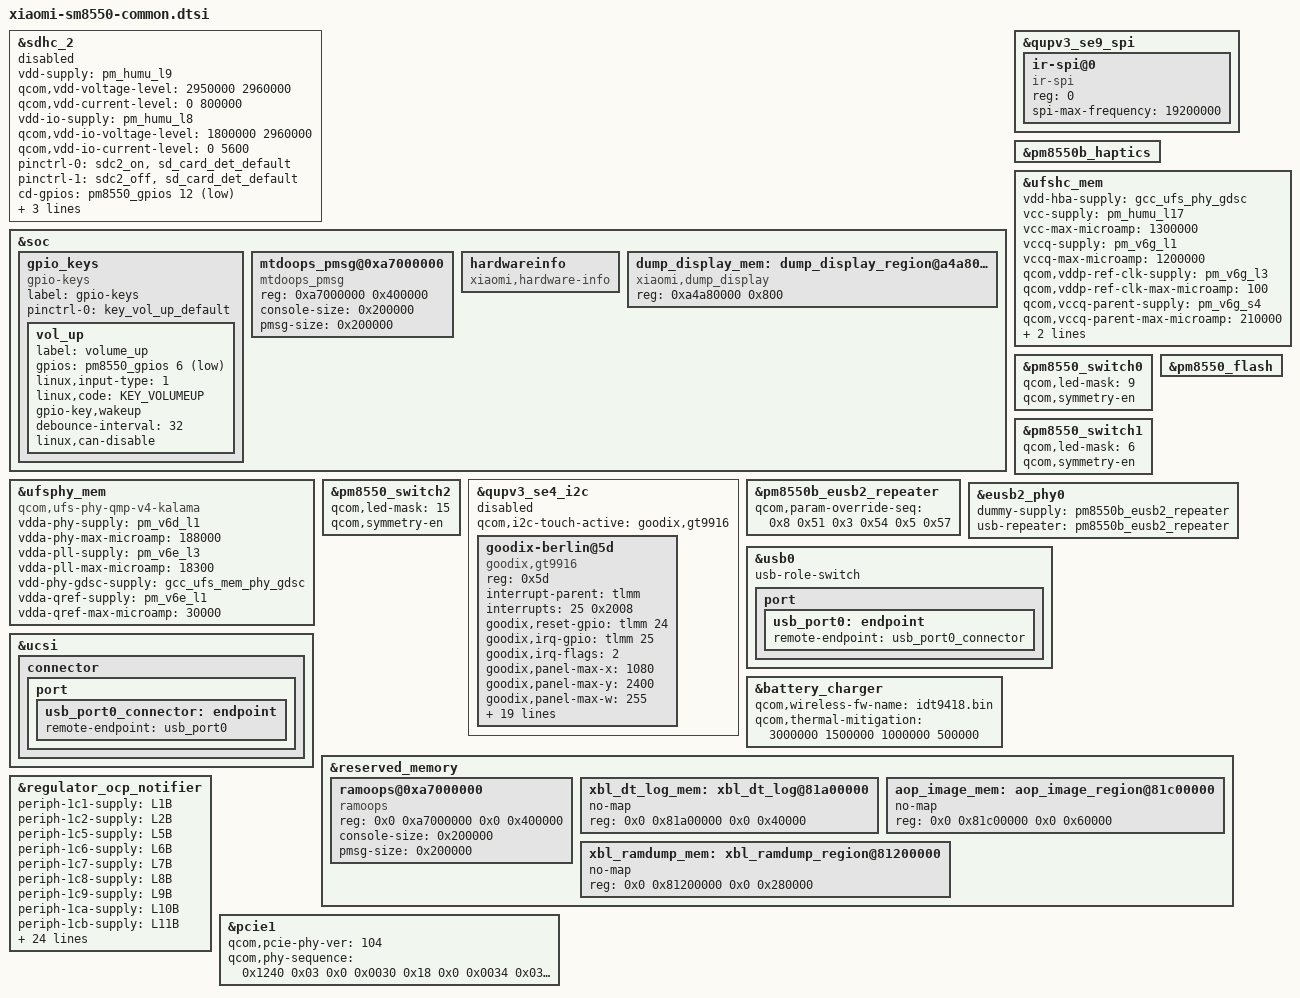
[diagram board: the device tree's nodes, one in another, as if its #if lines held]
#include <dt-bindings/gpio/gpio.h>
#include <dt-bindings/input/input.h>
#include <dt-bindings/clock/qcom,gcc-kalama.h>

#include "kalama-pmic-overlay.dtsi"
#include "kalama-thermal-overlay.dtsi"

&sdhc_2 {
	status = "disabled";
	vdd-supply = <&pm_humu_l9>;
	qcom,vdd-voltage-level = <2950000 2960000>;
	qcom,vdd-current-level = <0 800000>;

	vdd-io-supply = <&pm_humu_l8>;
	qcom,vdd-io-voltage-level = <1800000 2960000>;
	qcom,vdd-io-current-level = <0 5600>;

	pinctrl-names = "default", "sleep";
	pinctrl-0 = <&sdc2_on>, <&sd_card_det_default>;
	pinctrl-1 = <&sdc2_off>, <&sd_card_det_default>;

	cd-gpios = <&pm8550_gpios 12 GPIO_ACTIVE_LOW>;

	resets = <&gcc GCC_SDCC2_BCR>;
	reset-names = "core_reset";

	qcom,iommu-dma = "fastmap";
	qcom,uses_level_shifter;
};

&soc {
	gpio_keys {
		compatible = "gpio-keys";
		label = "gpio-keys";

		pinctrl-names = "default";
		pinctrl-0 = <&key_vol_up_default>;

		vol_up {
			label = "volume_up";
			gpios = <&pm8550_gpios 6 GPIO_ACTIVE_LOW>;
			linux,input-type = <1>;
			linux,code = <KEY_VOLUMEUP>;
			gpio-key,wakeup;
			debounce-interval = <32>;
			linux,can-disable;
		};
	};

	mtdoops_pmsg@0xa7000000 {
		compatible = "mtdoops_pmsg";
		reg = <0xa7000000 0x400000>;
		console-size = <0x200000>;
		pmsg-size = <0x200000>;
	};

	hardwareinfo {
		compatible = "xiaomi,hardware-info";
		status = "ok";
	};

	dump_display_mem: dump_display_region@a4a80000 {
		compatible = "xiaomi,dump_display";
		reg = <0xa4a80000  0x800>;
	};
};

&qupv3_se9_spi {
	status = "ok";
	ir-spi@0 {
		compatible = "ir-spi";
		reg = <0>;
		spi-max-frequency = <19200000>;
		status = "ok";
	};
};

&pm8550b_haptics {
	status = "okay";
};

&ufsphy_mem {
	compatible = "qcom,ufs-phy-qmp-v4-kalama";

	/* VDDA_UFS_CORE */
	vdda-phy-supply = <&pm_v6d_l1>;
	vdda-phy-max-microamp = <188000>;

	/* VDDA_UFS_0_1P2 */
	vdda-pll-supply = <&pm_v6e_l3>;
	vdda-pll-max-microamp = <18300>;

	/* Phy GDSC for VDD_MX, always on */
	vdd-phy-gdsc-supply = <&gcc_ufs_mem_phy_gdsc>;

	/* Qref power supply, Refer Qref diagram */
	vdda-qref-supply = <&pm_v6e_l1>;
	vdda-qref-max-microamp = <30000>;

	status = "ok";
};

&ufshc_mem {
	vdd-hba-supply = <&gcc_ufs_phy_gdsc>;

	vcc-supply = <&pm_humu_l17>;
	vcc-max-microamp = <1300000>;

	vccq-supply = <&pm_v6g_l1>;
	vccq-max-microamp = <1200000>;

	/* VDD_PX10 is voted for the ufs_reset_n */
	qcom,vddp-ref-clk-supply = <&pm_v6g_l3>;
	qcom,vddp-ref-clk-max-microamp = <100>;

	qcom,vccq-parent-supply = <&pm_v6g_s4>;
	qcom,vccq-parent-max-microamp = <210000>;

	reset-gpios = <&tlmm 210 GPIO_ACTIVE_LOW>;
	resets = <&gcc GCC_UFS_PHY_BCR>;
	reset-names = "rst";

	status = "ok";
};

&pm8550_switch0 {
	qcom,led-mask = <9>; /* Channels 1 & 4 */
	qcom,symmetry-en;
};

&pm8550_switch1 {
	qcom,led-mask = <6>; /* Channels 2 & 3 */
	qcom,symmetry-en;
};

&pm8550_switch2 {
	qcom,led-mask = <15>; /* All Channels */
	qcom,symmetry-en;
};

&pm8550_flash {
	status = "ok";
};


&qupv3_se4_i2c {
	#address-cells = <1>;
	#size-cells = <0>;

	status = "disabled";
	qcom,i2c-touch-active = "goodix,gt9916";

	goodix-berlin@5d {
		compatible = "goodix,gt9916";
		reg = <0x5d>;
		interrupt-parent = <&tlmm>;
		interrupts = <25 0x2008>;
		goodix,reset-gpio = <&tlmm 24 0x00>;
		goodix,irq-gpio = <&tlmm 25 0x2008>;
		goodix,irq-flags = <2>;
		goodix,panel-max-x = <1080>;
		goodix,panel-max-y = <2400>;
		goodix,panel-max-w = <255>;
		goodix,panel-max-p = <4096>;
		goodix,firmware-name = "goodix_firmware_i2c.bin";
		goodix,config-name = "goodix_cfg_group_i2c.bin";
		goodix,avdd-name = "avdd";
		goodix,iovdd-name = "iovdd";
		invert_xy;
		avdd-supply = <&L14B>;
		iovdd-supply = <&L12B>;
		goodix,touch-type = "primary";
		goodix,qts_en;
		qts,trusted-touch-mode = "vm_mode";
		qts,touch-environment = "pvm";
		qts,trusted-touch-type = "primary";
		qts,trusted-touch-spi-irq = <569>;
		qts,trusted-touch-io-bases = <0xa90000>;
		qts,trusted-touch-io-sizes = <0x1000>;
		qts,trusted-touch-vm-gpio-list = <&tlmm 44 0 &tlmm 45 0 &tlmm 46 0
						&tlmm 47 0 &tlmm 24 0 &tlmm 25 0x2008>;
	};
};

&pm8550b_eusb2_repeater {
	qcom,param-override-seq =
		/* <value reg_offset> */
		/* Adjust HS trasmit amplitude */
		<0x8 0x51
		/* Squelch detection threshold */
		 0x3 0x54
		/* Tx pre-emphasis tuning */
		 0x5 0x57>;
};

&eusb2_phy0 {
	dummy-supply = <&pm8550b_eusb2_repeater>;
	usb-repeater = <&pm8550b_eusb2_repeater>;
};

&usb0 {
	usb-role-switch;
	port {
		usb_port0: endpoint {
			remote-endpoint = <&usb_port0_connector>;
		};
	};
};

&ucsi {
	connector {
		port {
			usb_port0_connector: endpoint {
				remote-endpoint = <&usb_port0>;
			};
		};
	};
};

&battery_charger {
	qcom,wireless-fw-name = "idt9418.bin";
	qcom,thermal-mitigation = <3000000 1500000 1000000 500000>;
};

&reserved_memory {
	#address-cells = <2>;
	#size-cells = <2>;
	ranges;

	ramoops@0xa7000000 {
		compatible = "ramoops";
		reg = <0x0 0xa7000000 0x0 0x400000>;
		console-size = <0x200000>;
		pmsg-size = <0x200000>;
	};

	// xiami splits xbl_dt_log_merged_mem into the following
	// 3 regions, just like older days
	xbl_dt_log_mem: xbl_dt_log@81a00000 {
	       no-map;
	       reg = <0x0 0x81a00000 0x0 0x40000>;
	};

	aop_image_mem: aop_image_region@81c00000 {
	       no-map;
	       reg = <0x0 0x81c00000 0x0 0x60000>;
	};

	xbl_ramdump_mem: xbl_ramdump_region@81200000 {
		no-map;
		reg = <0x0 0x81200000 0x0 0x280000>;
	};
};
#if defined(ISHTAR_REGULATOR_OCP)
&regulator_ocp_notifier {
        periph-1c1-supply = <&L1B>;
        periph-1c2-supply = <&L2B>;
        periph-1c5-supply = <&L5B>;
        periph-1c6-supply = <&L6B>;
        periph-1c7-supply = <&L7B>;
        periph-1c8-supply = <&L8B>;
        periph-1c9-supply = <&L9B>;
        periph-1ca-supply = <&L10B>;
        periph-1cb-supply = <&L11B>;
        periph-1cc-supply = <&L12B>;
        periph-1ce-supply = <&L14B>;
        periph-1cf-supply = <&L15B>;
        periph-1d0-supply = <&L16B>;
        periph-1d1-supply = <&L17B>;
        periph-2c1-supply = <&L1C>;
        periph-3c1-supply = <&L1D>;
        periph-3c2-supply = <&L2D_LEVEL>;
        periph-4c1-supply = <&L1E>;
        periph-4c2-supply = <&L2E>;
        periph-4c3-supply = <&L3E>;
        periph-5c1-supply = <&L1F>;
        periph-5c2-supply = <&L2F>;
        periph-5c3-supply = <&L3F>;
        periph-6c1-supply = <&L1G>;
        periph-6c2-supply = <&L2G>;
        periph-6c3-supply = <&L3G>;
        periph-ac1-supply = <&L1K>;
        periph-ac2-supply = <&L2K>;
        periph-ac3-supply = <&L3K>;
        periph-ac4-supply = <&L4K>;
        periph-ac5-supply = <&L5K>;
        periph-ac6-supply = <&L6K>;
        periph-ac7-supply = <&L7K>;
};
#elif defined(VERMEER_REGULATOR_OCP)
&regulator_ocp_notifier {
        periph-1c1-supply = <&L1B>;
        periph-1c2-supply = <&L2B>;
        periph-1c5-supply = <&L5B>;
        periph-1c6-supply = <&L6B>;
        periph-1c7-supply = <&L7B>;
        periph-1c8-supply = <&L8B>;
        periph-1c9-supply = <&L9B>;
        periph-1ca-supply = <&L10B>;
        periph-1cb-supply = <&L11B>;
        periph-1cc-supply = <&L12B>;
        periph-1ce-supply = <&L14B>;
        periph-1cf-supply = <&L15B>;
        periph-1d0-supply = <&L16B>;
        periph-1d1-supply = <&L17B>;
        periph-2c1-supply = <&L1C>;
        periph-3c1-supply = <&L1D>;
        periph-3c2-supply = <&L2D_LEVEL>;
        periph-4c1-supply = <&L1E>;
        periph-4c2-supply = <&L2E>;
        periph-4c3-supply = <&L3E>;
        periph-5c1-supply = <&L1F>;
        periph-5c2-supply = <&L2F>;
        periph-5c3-supply = <&L3F>;
        periph-6c1-supply = <&L1G>;
        periph-6c2-supply = <&L2G>;
        periph-6c3-supply = <&L3G>;
        periph-ac1-supply = <&L1K>;
        periph-ac2-supply = <&L2K>;
        periph-ac3-supply = <&L3K>;
        periph-ac4-supply = <&L4K>;
        periph-ac5-supply = <&L5K>;
        periph-ac6-supply = <&L6K>;
        periph-ac7-supply = <&L7K>;
};
#elif defined(BABYLON_REGULATOR_OCP)
&regulator_ocp_notifier {
        periph-1c1-supply = <&L1B>;
        periph-1c2-supply = <&L2B>;
        periph-1c5-supply = <&L5B>;
        periph-1c6-supply = <&L6B>;
        periph-1c7-supply = <&L7B>;
        periph-1c8-supply = <&L8B>;
        periph-1c9-supply = <&L9B>;
        periph-1ca-supply = <&L10B>;
        periph-1cb-supply = <&L11B>;
        periph-1cc-supply = <&L12B>;
        periph-1ce-supply = <&L14B>;
        periph-1cf-supply = <&L15B>;
        periph-1d0-supply = <&L16B>;
        periph-1d1-supply = <&L17B>;
        periph-2c1-supply = <&L1C>;
        periph-3c1-supply = <&L1D>;
        periph-3c2-supply = <&L2D_LEVEL>;
        periph-4c1-supply = <&L1E>;
        periph-4c2-supply = <&L2E>;
        periph-4c3-supply = <&L3E>;
        periph-5c1-supply = <&L1F>;
        periph-5c2-supply = <&L2F>;
        periph-5c3-supply = <&L3F>;
        periph-6c1-supply = <&L1G>;
        periph-6c2-supply = <&L2G>;
        periph-6c3-supply = <&L3G>;
        periph-ac1-supply = <&L1K>;
        periph-ac2-supply = <&L2K>;
        periph-ac3-supply = <&L3K>;
        periph-ac4-supply = <&L4K>;
        periph-ac5-supply = <&L5K>;
        periph-ac6-supply = <&L6K>;
        periph-ac7-supply = <&L7K>;
};
#elif defined(SOCRATES_REGULATOR_OCP)
&regulator_ocp_notifier {
	periph-1c1-supply = <&L1B>;
	periph-1c2-supply = <&L2B>;
	periph-1c5-supply = <&L5B>;
	periph-1c6-supply = <&L6B>;
	periph-1c7-supply = <&L7B>;
	periph-1c8-supply = <&L8B>;
	periph-1c9-supply = <&L9B>;
	periph-1ca-supply = <&L10B>;
	periph-1cb-supply = <&L11B>;
	periph-1cc-supply = <&L12B>;
	periph-1cd-supply = <&L13B>;
	periph-1ce-supply = <&L14B>;
	periph-1cf-supply = <&L15B>;
	periph-1d0-supply = <&L16B>;
	periph-1d1-supply = <&L17B>;
	periph-2c1-supply = <&L1C>;
	periph-3c1-supply = <&L1D>;
	periph-3c2-supply = <&L2D_LEVEL>;
	periph-4c1-supply = <&L1E>;
	periph-4c2-supply = <&L2E>;
	periph-4c3-supply = <&L3E>;
	periph-5c1-supply = <&L1F>;
	periph-5c2-supply = <&L2F>;
	periph-5c3-supply = <&L3F>;
	periph-6c1-supply = <&L1G>;
	periph-6c2-supply = <&L2G>;
	periph-6c3-supply = <&L3G>;
	periph-ac1-supply = <&L1K>;
	periph-ac2-supply = <&L2K>;
	periph-ac3-supply = <&L3K>;
	periph-ac4-supply = <&L4K>;
	periph-ac5-supply = <&L5K>;
	periph-ac6-supply = <&L6K>;
	periph-ac7-supply = <&L7K>;
};
#elif defined(FUXI_NUWA_REGULATOR_OCP)
&regulator_ocp_notifier {
        periph-1c1-supply = <&L1B>;
        periph-1c2-supply = <&L2B>;
        periph-1c5-supply = <&L5B>;
        periph-1c6-supply = <&L6B>;
        periph-1c7-supply = <&L7B>;
        periph-1c8-supply = <&L8B>;
        periph-1c9-supply = <&L9B>;
        periph-1ca-supply = <&L10B>;
        periph-1cb-supply = <&L11B>;
        periph-1cc-supply = <&L12B>;
        periph-1cd-supply = <&L13B>;
        periph-1ce-supply = <&L14B>;
        periph-1cf-supply = <&L15B>;
        periph-1d0-supply = <&L16B>;
        periph-1d1-supply = <&L17B>;
        periph-2c1-supply = <&L1C>;
        periph-3c1-supply = <&L1D>;
        periph-3c2-supply = <&L2D_LEVEL>;
        periph-4c1-supply = <&L1E>;
        periph-4c2-supply = <&L2E>;
        periph-4c3-supply = <&L3E>;
        periph-5c1-supply = <&L1F>;
        periph-5c2-supply = <&L2F>;
        periph-5c3-supply = <&L3F>;
        periph-6c1-supply = <&L1G>;
        periph-6c2-supply = <&L2G>;
        periph-6c3-supply = <&L3G>;
        periph-ac1-supply = <&L1K>;
        periph-ac2-supply = <&L2K>;
        periph-ac3-supply = <&L3K>;
        periph-ac4-supply = <&L4K>;
        periph-ac5-supply = <&L5K>;
        periph-ac6-supply = <&L6K>;
        periph-ac7-supply = <&L7K>;
        periph-c40-supply = <&L1M>;
        periph-c41-supply = <&L2M>;
        periph-c42-supply = <&L3M>;
        periph-c43-supply = <&L4M>;
        periph-c44-supply = <&L5M>;
        periph-c45-supply = <&L6M>;
        periph-c46-supply = <&L7M>;
};
#else
&regulator_ocp_notifier {
	periph-1c1-supply = <&L1B>;
	periph-1c2-supply = <&L2B>;
	periph-1c5-supply = <&L5B>;
	periph-1c6-supply = <&L6B>;
	periph-1c7-supply = <&L7B>;
	periph-1c8-supply = <&L8B>;
	periph-1c9-supply = <&L9B>;
	periph-1ca-supply = <&L10B>;
	periph-1cb-supply = <&L11B>;
	periph-1cc-supply = <&L12B>;
	periph-1cd-supply = <&L13B>;
	periph-1ce-supply = <&L14B>;
	periph-1cf-supply = <&L15B>;
	periph-1d0-supply = <&L16B>;
	periph-1d1-supply = <&L17B>;
	periph-2c1-supply = <&L1C>;
	periph-2c3-supply = <&L3C>;
	periph-3c1-supply = <&L1D>;
	periph-3c2-supply = <&L2D_LEVEL>;
	periph-4c1-supply = <&L1E>;
	periph-4c2-supply = <&L2E>;
	periph-4c3-supply = <&L3E>;
	periph-5c1-supply = <&L1F>;
	periph-5c2-supply = <&L2F>;
	periph-5c3-supply = <&L3F>;
	periph-6c1-supply = <&L1G>;
	periph-6c2-supply = <&L2G>;
	periph-6c3-supply = <&L3G>;
	periph-ac1-supply = <&L1K>;
	periph-ac2-supply = <&L2K>;
	periph-ac3-supply = <&L3K>;
	periph-ac4-supply = <&L4K>;
	periph-ac5-supply = <&L5K>;
	periph-ac6-supply = <&L6K>;
	periph-ac7-supply = <&L7K>;
	periph-bc3-supply = <&L3L>;
	periph-bc4-supply = <&L4L>;
	periph-bc5-supply = <&L5L>;
	periph-bc6-supply = <&L6L>;
	periph-bc7-supply = <&L7L>;
	periph-c40-supply = <&L1M>;
	periph-c41-supply = <&L2M>;
	periph-c42-supply = <&L3M>;
	periph-c43-supply = <&L4M>;
	periph-c44-supply = <&L5M>;
	periph-c45-supply = <&L6M>;
	periph-c46-supply = <&L7M>;
	periph-d40-supply = <&L1N>;
	periph-d41-supply = <&L2N>;
	periph-d42-supply = <&L3N>;
	periph-d43-supply = <&L4N>;
	periph-d44-supply = <&L5N>;
	periph-d45-supply = <&L6N>;
	periph-d46-supply = <&L7N>;
};
#endif/*SOCRATES_REGULATOR_OCP*/

&pcie1 {
		qcom,pcie-phy-ver = <104>;

		qcom,phy-sequence = <0x1240 0x03 0x0
				0x0030 0x18 0x0
				0x0034 0x03 0x0
				0x0078 0x01 0x0
				0x007c 0x00 0x0
				0x0080 0x51 0x0
				0x0090 0x12 0x0
				0x00ac 0x34 0x0
				0x00b0 0x00 0x0
				0x00cc 0x00 0x0
				0x0208 0x0c 0x0
				0x020c 0x0a 0x0
				0x0218 0x04 0x0
				0x0220 0x16 0x0
				0x0234 0x00 0x0
				0x029c 0x80 0x0
				0x02a0 0x7c 0x0
				0x02ac 0x00 0x0
				0x02b0 0x20 0x0
				0x02b4 0x05 0x0
				0x02b8 0x00 0x0
				0x02e0 0x40 0x0
				0x02e4 0x00 0x0
				0x02e8 0x0a 0x0
				0x030c 0x0d 0x0
				0x0318 0x80 0x0
				0x031c 0x0a 0x0
				0x0320 0x0f 0x0 /* setting for ultra short channel */
				0x033c 0x74 0x0
				0x0340 0x00 0x0
				0x0348 0x1c 0x0
				0x034c 0x24 0x0
				0x0354 0x0e 0x0
				0x0388 0x20 0x0
				0x0390 0x28 0x0
				0x0394 0x30 0x0
				0x039c 0x0c 0x0
				0x03dc 0x09 0x0
				0x03f4 0x14 0x0
				0x03f8 0xb3 0x0
				0x03fc 0x58 0x0
				0x0400 0x9a 0x0
				0x0404 0x26 0x0
				0x0408 0xb6 0x0
				0x040c 0xee 0x0
				0x0410 0xdb 0x0
				0x0414 0xdb 0x0
				0x0418 0xa0 0x0
				0x041c 0xdf 0x0
				0x0420 0x78 0x0
				0x0424 0x76 0x0
				0x0428 0xff 0x0
				0x0830 0x18 0x0
				0x0834 0x03 0x0
				0x0878 0x01 0x0
				0x087c 0x00 0x0
				0x0880 0x51 0x0
				0x0890 0x12 0x0
				0x08ac 0x34 0x0
				0x08b0 0x00 0x0
				0x08cc 0x00 0x0
				0x0a08 0x0c 0x0
				0x0a0c 0x0a 0x0
				0x0a18 0x04 0x0
				0x0a20 0x16 0x0
				0x0a34 0x00 0x0
				0x0a9c 0x80 0x0
				0x0aa0 0x7c 0x0
				0x0aac 0x00 0x0
				0x0ab0 0x20 0x0
				0x0ab4 0x05 0x0
				0x0ab8 0x00 0x0
				0x0ae0 0x40 0x0
				0x0ae4 0x00 0x0
				0x0ae8 0x0a 0x0
				0x0b0c 0x0d 0x0
				0x0b18 0x80 0x0
				0x0b1c 0x0a 0x0
				0x0b20 0x0f 0x0 /* setting for ultra short channel */
				0x0b3c 0x74 0x0
				0x0b40 0x00 0x0
				0x0b48 0x1c 0x0
				0x0b4c 0x24 0x0
				0x0b54 0x0e 0x0
				0x0b88 0x20 0x0
				0x0b90 0x28 0x0
				0x0b94 0x30 0x0
				0x0b9c 0x0c 0x0
				0x0bdc 0x09 0x0
				0x0bf4 0x14 0x0
				0x0bf8 0xb3 0x0
				0x0bfc 0x58 0x0
				0x0c00 0x9a 0x0
				0x0c04 0x26 0x0
				0x0c08 0xb6 0x0
				0x0c0c 0xee 0x0
				0x0c10 0xdb 0x0
				0x0c14 0xdb 0x0
				0x0c18 0xa0 0x0
				0x0c1c 0xdf 0x0
				0x0c20 0x78 0x0
				0x0c24 0x76 0x0
				0x0c28 0xff 0x0
				0x0ea0 0x01 0x0
				0x0eb4 0x00 0x0
				0x0eb8 0x08 0x0
				0x0ebc 0x3e 0x0
				0x0ec0 0x1e 0x0
				0x0ec4 0x00 0x0
				0x0ec8 0x1f 0x0
				0x0ed4 0x12 0x0
				0x0ed8 0x12 0x0
				0x0edc 0xdb 0x0
				0x0ee0 0x9a 0x0
				0x0ee4 0x3f 0x0 /* setting for ultra short channel */
				0x0ee8 0xb6 0x0
				0x0eec 0x64 0x0
				0x0ef0 0x1f 0x0
				0x0ef4 0x1f 0x0
				0x0ef8 0x1f 0x0
				0x0efc 0x1f 0x0
				0x0f00 0x1f 0x0
				0x0f04 0x1f 0x0
				0x0f0c 0x1f 0x0
				0x0f14 0x1f 0x0
				0x0f1c 0x1f 0x0
				0x0f28 0x5b 0x0
				0x1000 0x26 0x0
				0x1004 0x03 0x0
				0x1010 0x06 0x0
				0x1014 0x16 0x0
				0x1018 0x36 0x0
				0x101c 0x04 0x0
				0x1020 0x0a 0x0
				0x1024 0x1a 0x0
				0x1028 0x68 0x0
				0x1030 0xab 0x0
				0x1034 0xaa 0x0
				0x1038 0x02 0x0
				0x103c 0x12 0x0
				0x1060 0xf8 0x0
				0x1064 0x01 0x0
				0x1070 0x06 0x0
				0x1074 0x16 0x0
				0x1078 0x36 0x0
				0x107c 0x0a 0x0
				0x1080 0x04 0x0
				0x1084 0x0d 0x0
				0x1088 0x41 0x0
				0x1090 0xab 0x0
				0x1094 0xaa 0x0
				0x1098 0x01 0x0
				0x109c 0x00 0x0
				0x10bc 0x0a 0x0
				0x10c0 0x01 0x0
				0x10cc 0x62 0x0
				0x10d0 0x02 0x0
				0x10d8 0x40 0x0
				0x10dc 0x14 0x0
				0x10e0 0x90 0x0
				0x10e4 0x82 0x0
				0x10f4 0x0f 0x0
				0x1110 0x08 0x0
				0x1120 0x46 0x0
				0x1124 0x04 0x0
				0x1140 0x14 0x0
				0x1164 0x34 0x0
				0x1170 0xa0 0x0
				0x1174 0x06 0x0
				0x1184 0x88 0x0
				0x1188 0x14 0x0
				0x118c 0x00 0x0
				0x1190 0x64 0x0
				0x1194 0x00 0x0
				0x1198 0x0f 0x0
				0x1378 0x2e 0x0
				0x1390 0xcc 0x0
				0x13f0 0x0d 0x0
				0x13f8 0x00 0x0
				0x13fc 0x22 0x0
				0x141c 0xc1 0x0
				0x1490 0x00 0x0
				0x14a0 0x16 0x0
				0x14f0 0x27 0x0
				0x14f4 0x27 0x0
				0x14fc 0x0d 0x0
				0x1508 0x02 0x0
				0x155c 0x2e 0x0
				0x157c 0x03 0x0
				0x1584 0x28 0x0
				0x13dc 0x04 0x0
				0x13e0 0x02 0x0
				0x1418 0xc0 0x0
				0x140c 0x1d 0x0
				0x158c 0x0f 0x0
				0x1370 0x0f 0x0 /* setting for ultra short channel */
				0x15ac 0xf2 0x0
				0x15c0 0xf2 0x0
				0x1200 0x00 0x0
				0x1244 0x03 0x0>;
};
